AUTOSAR XML (schema 00049)
package /PlanningApp
  process design PlanningDesign: executable=planningd
package /PlanningApp/exe
  executable planningd: category=APPLICATION_LEVEL, logging-behavior=USES-LOGGING, reporting-behavior=REPORTS-EXECUTION-STATE
    root sw component prototype pl_root: application-type=Planning
package /PlanningApp/swc
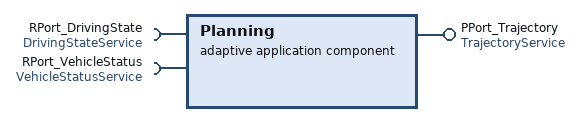
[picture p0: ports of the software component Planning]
  adaptive application sw component type Planning  # Spatial MPC over a 20-step horizon. Consumes the fused state and ego speed, produces a trajectory. Owns no device and speaks to no chassis.
    require port RPort_DrivingState: required-interface=DrivingStateService  # cte, epsi, kappa, hasCipo, cipoVelocity, cipoDistance.
    require port RPort_VehicleStatus: required-interface=VehicleStatusService  # ego_v. When this is stale or invalid the planner must not run — a plan computed against an assumed speed is worse than no plan.
    provide port PPort_Trajectory: provided-interface=TrajectoryService  # Trajectory out.
